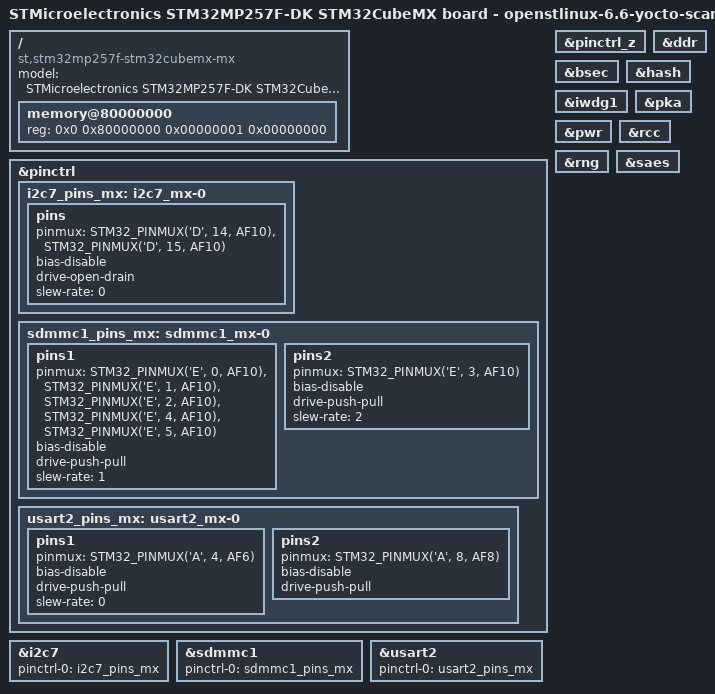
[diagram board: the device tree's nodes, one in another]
// SPDX-License-Identifier: (GPL-2.0-only OR BSD-3-Clause)
/*
 * Copyright (C) 2026, STMicroelectronics - All Rights Reserved
 * Author: STM32CubeMX code generation for STMicroelectronics.
 */

/* For more information on Device Tree configuration, please refer to
 * https://wiki.st.com/stm32mpu/wiki/Category:Device_tree_configuration
 */

/dts-v1/;

#include <dt-bindings/pinctrl/stm32-pinfunc.h>
#include <dt-bindings/clock/stm32mp25-clksrc.h>
#include "stm32mp25-mx.dtsi"

#include "stm32mp257.dtsi"
#include "stm32mp25xf.dtsi"
#include "stm32mp257f-stm32cubemx-mx-rcc.dtsi"
#include "stm32mp25xxak-pinctrl.dtsi"
#include "stm32mp25-ddr.dtsi"

/* USER CODE BEGIN includes */
/* USER CODE END includes */

/ {
	model = "STMicroelectronics STM32MP257F-DK STM32CubeMX board - openstlinux-6.6-yocto-scarthgap-mpu-v26.06.10";
	compatible = "st,stm32mp257f-stm32cubemx-mx", "st,stm32mp257f-dk", "st,stm32mp257";

	memory@80000000 {
		device_type = "memory";
		reg = <0x0 0x80000000 0x00000001 0x00000000>;

		/* USER CODE BEGIN memory */
		/* USER CODE END memory */
	};

	/* USER CODE BEGIN root */
	/* USER CODE END root */

}; /*root*/

&pinctrl {
	i2c7_pins_mx: i2c7_mx-0 {
		pins {
			pinmux = <STM32_PINMUX('D', 14, AF10)>, /* I2C7_SDA */
					 <STM32_PINMUX('D', 15, AF10)>; /* I2C7_SCL */
			bias-disable;
			drive-open-drain;
			slew-rate = <0>;
		};
	};

	sdmmc1_pins_mx: sdmmc1_mx-0 {
		pins1 {
			pinmux = <STM32_PINMUX('E', 0, AF10)>, /* SDMMC1_D2 */
					 <STM32_PINMUX('E', 1, AF10)>, /* SDMMC1_D3 */
					 <STM32_PINMUX('E', 2, AF10)>, /* SDMMC1_CMD */
					 <STM32_PINMUX('E', 4, AF10)>, /* SDMMC1_D0 */
					 <STM32_PINMUX('E', 5, AF10)>; /* SDMMC1_D1 */
			bias-disable;
			drive-push-pull;
			slew-rate = <1>;
		};
		pins2 {
			pinmux = <STM32_PINMUX('E', 3, AF10)>; /* SDMMC1_CK */
			bias-disable;
			drive-push-pull;
			slew-rate = <2>;
		};
	};

	usart2_pins_mx: usart2_mx-0 {
		pins1 {
			pinmux = <STM32_PINMUX('A', 4, AF6)>; /* USART2_TX */
			bias-disable;
			drive-push-pull;
			slew-rate = <0>;
		};
		pins2 {
			pinmux = <STM32_PINMUX('A', 8, AF8)>; /* USART2_RX */
			bias-disable;
			drive-push-pull;
		};
	};

	/* USER CODE BEGIN pinctrl */
	/* USER CODE END pinctrl */
};

&pinctrl_z {
	/* USER CODE BEGIN pinctrl_z */
	/* USER CODE END pinctrl_z */
};

&bsec {
	status = "okay";

	/* USER CODE BEGIN bsec */
	/* USER CODE END bsec */
};

&ddr {
	status = "okay";

	/* USER CODE BEGIN ddr */
	/* USER CODE END ddr */
};

&hash {
	status = "okay";

	/* USER CODE BEGIN hash */
	/* USER CODE END hash */
};

&i2c7 {
	pinctrl-names = "default";
	pinctrl-0 = <&i2c7_pins_mx>;
	status = "okay";

	/* USER CODE BEGIN i2c7 */
	/* USER CODE END i2c7 */
};

&iwdg1 {
	status = "okay";

	/* USER CODE BEGIN iwdg1 */
	/* USER CODE END iwdg1 */
};

&pka {
	status = "okay";

	/* USER CODE BEGIN pka */
	/* USER CODE END pka */
};

&pwr {
	status = "okay";

	/* USER CODE BEGIN pwr */
	/* USER CODE END pwr */
};

&rcc {
	status = "okay";

	/* USER CODE BEGIN rcc */
	/* USER CODE END rcc */
};

&rng {
	status = "okay";

	/* USER CODE BEGIN rng */
	/* USER CODE END rng */
};

&saes {
	status = "okay";

	/* USER CODE BEGIN saes */
	/* USER CODE END saes */
};

&sdmmc1 {
	pinctrl-names = "default";
	pinctrl-0 = <&sdmmc1_pins_mx>;
	status = "okay";

	/* USER CODE BEGIN sdmmc1 */
	/* USER CODE END sdmmc1 */
};

&usart2 {
	pinctrl-names = "default";
	pinctrl-0 = <&usart2_pins_mx>;
	status = "okay";

	/* USER CODE BEGIN usart2 */
	/* USER CODE END usart2 */
};

/* USER CODE BEGIN addons */
/* USER CODE END addons */

